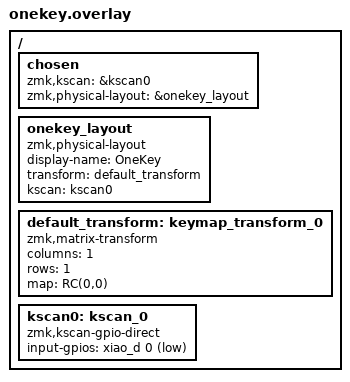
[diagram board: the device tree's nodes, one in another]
#include <dt-bindings/zmk/matrix_transform.h>

/ {
    chosen {
        zmk,kscan = &kscan0;
        zmk,physical-layout = &onekey_layout; // ★必須化されたレイアウト指定
    };

    onekey_layout: onekey_layout {
        compatible = "zmk,physical-layout";
        display-name = "OneKey";
        transform = <&default_transform>;
        kscan = <&kscan0>;
    };

    default_transform: keymap_transform_0 {
        compatible = "zmk,matrix-transform";
        columns = <1>;
        rows = <1>;
        map = < RC(0,0) >;
    };

    kscan0: kscan_0 {
        compatible = "zmk,kscan-gpio-direct";
        input-gpios = <&xiao_d 0 (GPIO_ACTIVE_LOW | GPIO_PULL_UP)>;
    };
};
